# COMPUTE_CLUSTER0_C71SS0_ECC_AGGR register map
Vendor: Texas Instruments
Peripheral module from a debugger description file (folder J7ES).
Registers are 32-bit, access not given, reset 0x0 unless marked. A register's access mark holds for its fields unless they carry their own. Offsets are as the file gives them; lines under a group give offsets from that group; [hi:lo] are bit positions; {n}, {i} and the like mark numbered series; 'fields as' and 'values as' point back to an identical list; <NAME> marks a mode.

## COMPUTE_CLUSTER0_C71SS0_ECC_AGGR
0x00 C71SS_ECC_REV ro reset 0x66A0EA00 — IP revision register.
  [31:0] REV — TI internal data. Identifies revision of peripheral.
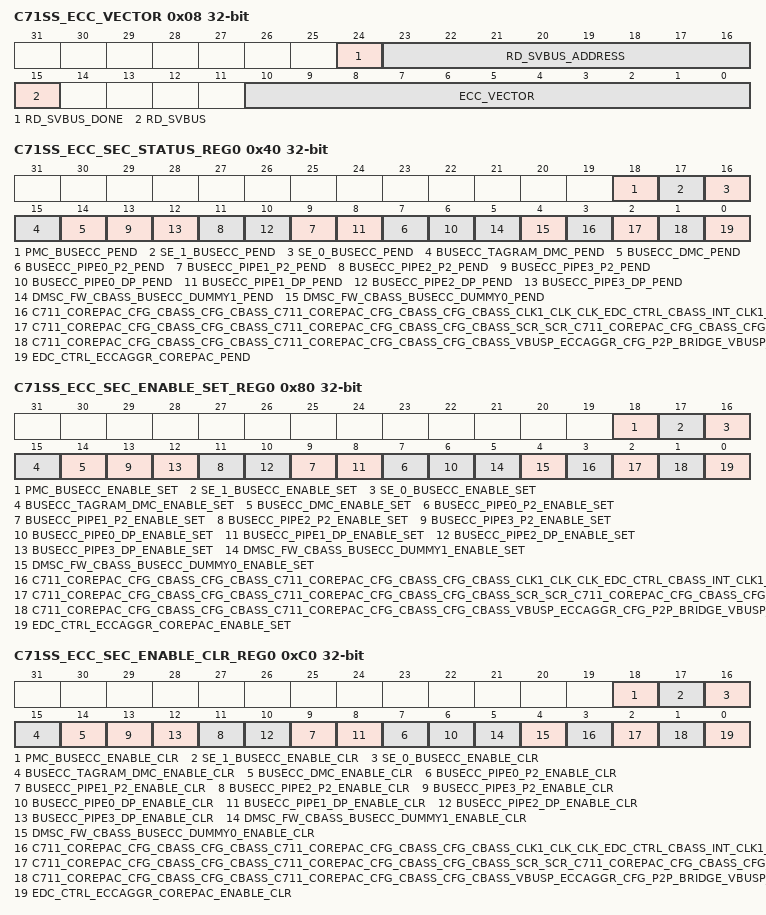
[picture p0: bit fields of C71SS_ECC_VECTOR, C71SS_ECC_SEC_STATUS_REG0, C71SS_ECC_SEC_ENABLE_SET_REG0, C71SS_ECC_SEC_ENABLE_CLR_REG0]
0x08 C71SS_ECC_VECTOR — ECC vector register.
  [24] RD_SVBUS_DONE — Status to indicate if read on serial VBUS is complete, write of any value will clear this bit. (access RW1C)
  [23:16] RD_SVBUS_ADDRESS rw — Read address
  [15] RD_SVBUS — Write 1 to trigger a read on the serial VBUS (access RW1S)
  [10:0] ECC_VECTOR rw — Value written to select the corresponding ECC RAM for control or status
0x0C C71SS_ECC_STAT ro reset 0x13 — Misc status register.
  [10:0] NUM_RAMS — Indicates the number of RAMs serviced by the ECC aggregator
0x3C C71SS_ECC_SEC_EOI_REG — SEC EOI register. The EOI register is used to re-trigger the pulse interrupt signal to ensure that any nested interrupt events are serviced. The software interrupt handler must write to the EOI register at the end of the current interrupt processing routine, so that new events can re-trigger the pulse interrupt signal again. For level interrupt signals the EOI register is not functional and must not be used.
  [0] EOI_WR — EOI value (access RW1S)
0x40 C71SS_ECC_SEC_STATUS_REG0 — SEC interrupt status register 0.
  [18] PMC_BUSECC_PEND — Interrupt pending status for PMC_BUSECC_PEND (access RW1S)
  [17] SE_1_BUSECC_PEND — Interrupt pending status for SE_1_BUSECC_PEND (access RW1S)
  [16] SE_0_BUSECC_PEND — Interrupt pending status for SE_0_BUSECC_PEND (access RW1S)
  [15] BUSECC_TAGRAM_DMC_PEND — Interrupt pending status for BUSECC_TAGRAM_DMC_PEND (access RW1S)
  [14] BUSECC_DMC_PEND — Interrupt pending status for BUSECC_DMC_PEND (access RW1S)
  [2n+7] BUSECC_PIPE{n}_P2_PEND (n=0..3) — Interrupt pending status for BUSECC_PIPE{n}_P2_PEND (access RW1S)
  [2n+6] BUSECC_PIPE{n}_DP_PEND (n=0..3) — Interrupt pending status for BUSECC_PIPE{n}_DP_PEND (access RW1S)
  [5] DMSC_FW_CBASS_BUSECC_DUMMY1_PEND — Interrupt pending status for DMSC_FW_CBASS_BUSECC_DUMMY1_PEND (access RW1S)
  [4] DMSC_FW_CBASS_BUSECC_DUMMY0_PEND — Interrupt pending status for DMSC_FW_CBASS_BUSECC_DUMMY0_PEND (access RW1S)
  [3] C711_COREPAC_CFG_CBASS_CFG_CBASS_C711_COREPAC_CFG_CBASS_CFG_CBASS_CLK1_CLK_CLK_EDC_CTRL_CBASS_INT_CLK1_CLK_BUSECC_PEND — Interrupt pending status for C711_COREPAC_CFG_CBASS_CFG_CBASS_C711_COREPAC_CFG_CBASS_CFG_CBASS_CLK1_CLK_CLK_EDC_CTRL_CBASS_INT_CLK1_CLK_BUSECC_PEND (access RW1S)
  [2] C711_COREPAC_CFG_CBASS_CFG_CBASS_C711_COREPAC_CFG_CBASS_CFG_CBASS_SCR_SCR_C711_COREPAC_CFG_CBASS_CFG_CBASS_SCR_SCR_EDC_CTRL_BUSECC_PEND — Interrupt pending status for C711_COREPAC_CFG_CBASS_CFG_CBASS_C711_COREPAC_CFG_CBASS_CFG_CBASS_SCR_SCR_C711_COREPAC_CFG_CBASS_CFG_CBASS_SCR_SCR_EDC_CTRL_BUSECC_PEND (access RW1S)
  [1] C711_COREPAC_CFG_CBASS_CFG_CBASS_C711_COREPAC_CFG_CBASS_CFG_CBASS_VBUSP_ECCAGGR_CFG_P2P_BRIDGE_VBUSP_ECCAGGR_CFG_BRIDGE_BUSECC_PEND — Interrupt pending status for C711_COREPAC_CFG_CBASS_CFG_CBASS_C711_COREPAC_CFG_CBASS_CFG_CBASS_VBUSP_ECCAGGR_CFG_P2P_BRIDGE_VBUSP_ECCAGGR_CFG_BRIDGE_BUSECC_PEND (access RW1S)
  [0] EDC_CTRL_ECCAGGR_COREPAC_PEND — Interrupt pending status for EDC_CTRL_ECCAGGR_COREPAC_PEND (access RW1S)
0x80 C71SS_ECC_SEC_ENABLE_SET_REG0 — SEC interrupt enable set register 0.
  [18] PMC_BUSECC_ENABLE_SET — Interrupt enable set for PMC_BUSECC_PEND (access RW1S)
  [17] SE_1_BUSECC_ENABLE_SET — Interrupt enable set for SE_1_BUSECC_PEND (access RW1S)
  [16] SE_0_BUSECC_ENABLE_SET — Interrupt enable set for SE_0_BUSECC_PEND (access RW1S)
  [15] BUSECC_TAGRAM_DMC_ENABLE_SET — Interrupt enable set for BUSECC_TAGRAM_DMC_PEND (access RW1S)
  [14] BUSECC_DMC_ENABLE_SET — Interrupt enable set for BUSECC_DMC_PEND (access RW1S)
  [2n+7] BUSECC_PIPE{n}_P2_ENABLE_SET (n=0..3) — Interrupt enable set for BUSECC_PIPE{n}_P2_PEND (access RW1S)
  [2n+6] BUSECC_PIPE{n}_DP_ENABLE_SET (n=0..3) — Interrupt enable set for BUSECC_PIPE{n}_DP_PEND (access RW1S)
  [5] DMSC_FW_CBASS_BUSECC_DUMMY1_ENABLE_SET — Interrupt enable set for DMSC_FW_CBASS_BUSECC_DUMMY1_PEND (access RW1S)
  [4] DMSC_FW_CBASS_BUSECC_DUMMY0_ENABLE_SET — Interrupt enable set for DMSC_FW_CBASS_BUSECC_DUMMY0_PEND (access RW1S)
  [3] C711_COREPAC_CFG_CBASS_CFG_CBASS_C711_COREPAC_CFG_CBASS_CFG_CBASS_CLK1_CLK_CLK_EDC_CTRL_CBASS_INT_CLK1_CLK_BUSECC_ENABLE_SET — Interrupt enable set for C711_COREPAC_CFG_CBASS_CFG_CBASS_C711_COREPAC_CFG_CBASS_CFG_CBASS_CLK1_CLK_CLK_EDC_CTRL_CBASS_INT_CLK1_CLK_BUSECC_PEND (access RW1S)
  [2] C711_COREPAC_CFG_CBASS_CFG_CBASS_C711_COREPAC_CFG_CBASS_CFG_CBASS_SCR_SCR_C711_COREPAC_CFG_CBASS_CFG_CBASS_SCR_SCR_EDC_CTRL_BUSECC_ENABLE_SET — Interrupt enable set for C711_COREPAC_CFG_CBASS_CFG_CBASS_C711_COREPAC_CFG_CBASS_CFG_CBASS_SCR_SCR_C711_COREPAC_CFG_CBASS_CFG_CBASS_SCR_SCR_EDC_CTRL_BUSECC_PEND (access RW1S)
  [1] C711_COREPAC_CFG_CBASS_CFG_CBASS_C711_COREPAC_CFG_CBASS_CFG_CBASS_VBUSP_ECCAGGR_CFG_P2P_BRIDGE_VBUSP_ECCAGGR_CFG_BRIDGE_BUSECC_ENABLE_SET — Interrupt enable set for C711_COREPAC_CFG_CBASS_CFG_CBASS_C711_COREPAC_CFG_CBASS_CFG_CBASS_VBUSP_ECCAGGR_CFG_P2P_BRIDGE_VBUSP_ECCAGGR_CFG_BRIDGE_BUSECC_PEND (access RW1S)
  [0] EDC_CTRL_ECCAGGR_COREPAC_ENABLE_SET — Interrupt enable set for EDC_CTRL_ECCAGGR_COREPAC_PEND (access RW1S)
0xC0 C71SS_ECC_SEC_ENABLE_CLR_REG0 — SEC interrupt enable clear register 0.
  [18] PMC_BUSECC_ENABLE_CLR — Interrupt enable clear for PMC_BUSECC_PEND (access RW1C)
  [17] SE_1_BUSECC_ENABLE_CLR — Interrupt enable clear for SE_1_BUSECC_PEND (access RW1C)
  [16] SE_0_BUSECC_ENABLE_CLR — Interrupt enable clear for SE_0_BUSECC_PEND (access RW1C)
  [15] BUSECC_TAGRAM_DMC_ENABLE_CLR — Interrupt enable clear for BUSECC_TAGRAM_DMC_PEND (access RW1C)
  [14] BUSECC_DMC_ENABLE_CLR — Interrupt enable clear for BUSECC_DMC_PEND (access RW1C)
  [2n+7] BUSECC_PIPE{n}_P2_ENABLE_CLR (n=0..3) — Interrupt enable clear for BUSECC_PIPE{n}_P2_PEND (access RW1C)
  [2n+6] BUSECC_PIPE{n}_DP_ENABLE_CLR (n=0..3) — Interrupt enable clear for BUSECC_PIPE{n}_DP_PEND (access RW1C)
  [5] DMSC_FW_CBASS_BUSECC_DUMMY1_ENABLE_CLR — Interrupt enable clear for DMSC_FW_CBASS_BUSECC_DUMMY1_PEND (access RW1C)
  [4] DMSC_FW_CBASS_BUSECC_DUMMY0_ENABLE_CLR — Interrupt enable clear for DMSC_FW_CBASS_BUSECC_DUMMY0_PEND (access RW1C)
  [3] C711_COREPAC_CFG_CBASS_CFG_CBASS_C711_COREPAC_CFG_CBASS_CFG_CBASS_CLK1_CLK_CLK_EDC_CTRL_CBASS_INT_CLK1_CLK_BUSECC_ENABLE_CLR — Interrupt enable clear for C711_COREPAC_CFG_CBASS_CFG_CBASS_C711_COREPAC_CFG_CBASS_CFG_CBASS_CLK1_CLK_CLK_EDC_CTRL_CBASS_INT_CLK1_CLK_BUSECC_PEND (access RW1C)
  [2] C711_COREPAC_CFG_CBASS_CFG_CBASS_C711_COREPAC_CFG_CBASS_CFG_CBASS_SCR_SCR_C711_COREPAC_CFG_CBASS_CFG_CBASS_SCR_SCR_EDC_CTRL_BUSECC_ENABLE_CLR — Interrupt enable clear for C711_COREPAC_CFG_CBASS_CFG_CBASS_C711_COREPAC_CFG_CBASS_CFG_CBASS_SCR_SCR_C711_COREPAC_CFG_CBASS_CFG_CBASS_SCR_SCR_EDC_CTRL_BUSECC_PEND (access RW1C)
  [1] C711_COREPAC_CFG_CBASS_CFG_CBASS_C711_COREPAC_CFG_CBASS_CFG_CBASS_VBUSP_ECCAGGR_CFG_P2P_BRIDGE_VBUSP_ECCAGGR_CFG_BRIDGE_BUSECC_ENABLE_CLR — Interrupt enable clear for C711_COREPAC_CFG_CBASS_CFG_CBASS_C711_COREPAC_CFG_CBASS_CFG_CBASS_VBUSP_ECCAGGR_CFG_P2P_BRIDGE_VBUSP_ECCAGGR_CFG_BRIDGE_BUSECC_PEND (access RW1C)
  [0] EDC_CTRL_ECCAGGR_COREPAC_ENABLE_CLR — Interrupt enable clear for EDC_CTRL_ECCAGGR_COREPAC_PEND (access RW1C)
0x13C C71SS_ECC_DED_EOI_REG — DED EOI register. The EOI register is used to re-trigger the pulse interrupt signal to ensure that any nested interrupt events are serviced. The software interrupt handler must write to the EOI register at the end of the current interrupt processing routine, so that new events can re-trigger the pulse interrupt signal again. For level interrupt signals the EOI register is not functional and must not be used.
  [0] EOI_WR — EOI value (access RW1S)
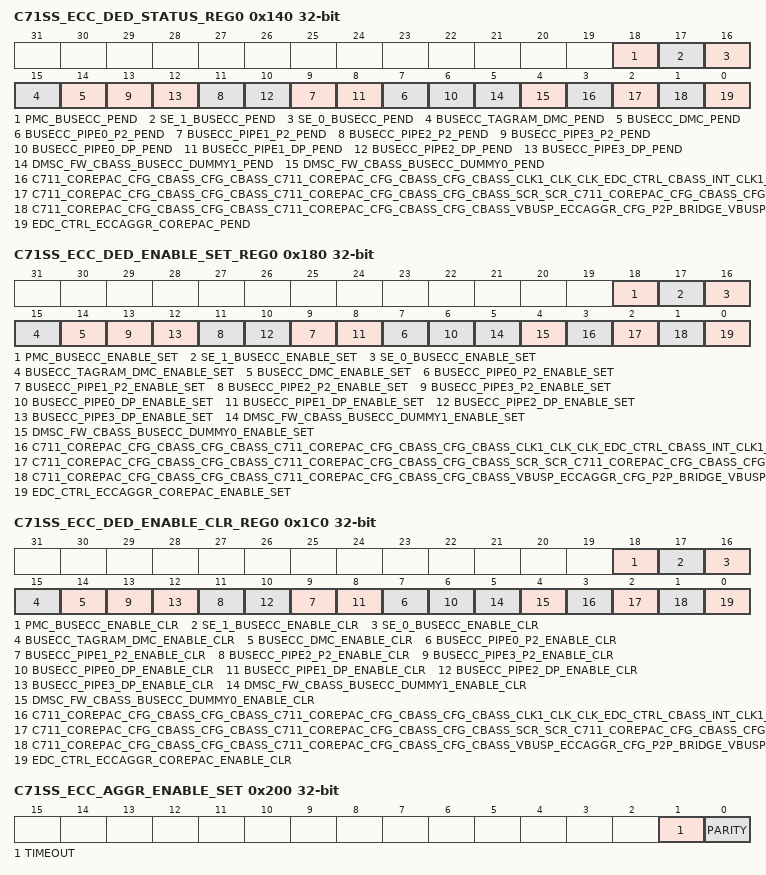
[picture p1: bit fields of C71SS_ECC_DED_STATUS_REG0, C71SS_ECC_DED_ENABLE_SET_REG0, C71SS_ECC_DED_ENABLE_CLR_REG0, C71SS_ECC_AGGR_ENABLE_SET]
0x140 C71SS_ECC_DED_STATUS_REG0 — DED interrupt status register 0.
  fields as C71SS_ECC_SEC_STATUS_REG0
0x180 C71SS_ECC_DED_ENABLE_SET_REG0 — DED interrupt enable set register 0.
  fields as C71SS_ECC_SEC_ENABLE_SET_REG0
0x1C0 C71SS_ECC_DED_ENABLE_CLR_REG0 — DED interrupt enable clear register 0.
  fields as C71SS_ECC_SEC_ENABLE_CLR_REG0
0x200 C71SS_ECC_AGGR_ENABLE_SET — AGGR interrupt enable set register.
  [1] TIMEOUT — Interrupt enable set for svbus timeout errors (access RW1S)
  [0] PARITY — Interrupt enable set for parity errors (access RW1S)
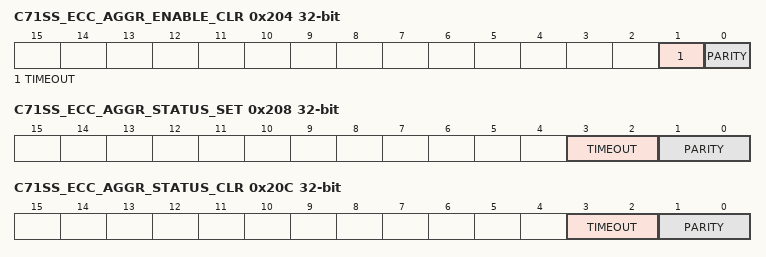
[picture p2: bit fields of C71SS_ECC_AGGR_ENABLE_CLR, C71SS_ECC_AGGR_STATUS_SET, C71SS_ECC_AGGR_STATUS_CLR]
0x204 C71SS_ECC_AGGR_ENABLE_CLR — AGGR interrupt enable clear register.
  [1] TIMEOUT — Interrupt enable clear for svbus timeout errors (access RW1C)
  [0] PARITY — Interrupt enable clear for parity errors (access RW1C)
0x208 C71SS_ECC_AGGR_STATUS_SET — AGGR interrupt status set register.
  [3:2] TIMEOUT — Interrupt status set for svbus timeout errors (access RWincr)
  [1:0] PARITY — Interrupt status set for parity errors (access RWincr)
0x20C C71SS_ECC_AGGR_STATUS_CLR — AGGR interrupt status clear register.
  [3:2] TIMEOUT — Interrupt status clear for svbus timeout errors (access RWdecr)
  [1:0] PARITY — Interrupt status clear for parity errors (access RWdecr)
